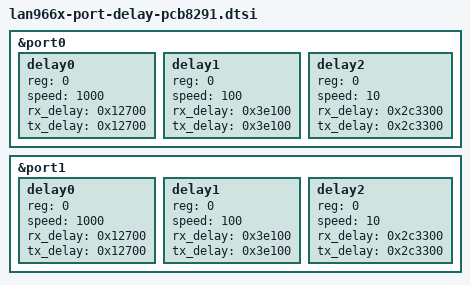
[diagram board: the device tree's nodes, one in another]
&port0 {
	#address-cells = <1>;
	#size-cells = <0>;

	delay0 {
		reg = <0>;
		speed = <1000>;
		rx_delay = <0x12700>;
		tx_delay = <0x12700>;
	};

	delay1 {
		reg = <0>;
		speed = <100>;
		rx_delay = <0x3e100>;
		tx_delay = <0x3e100>;
	};

	delay2 {
		reg = <0>;
		speed = <10>;
		rx_delay = <0x2c3300>;
		tx_delay = <0x2c3300>;
	};
};

&port1 {
	#address-cells = <1>;
	#size-cells = <0>;

	delay0 {
		reg = <0>;
		speed = <1000>;
		rx_delay = <0x12700>;
		tx_delay = <0x12700>;
	};

	delay1 {
		reg = <0>;
		speed = <100>;
		rx_delay = <0x3e100>;
		tx_delay = <0x3e100>;
	};

	delay2 {
		reg = <0>;
		speed = <10>;
		rx_delay = <0x2c3300>;
		tx_delay = <0x2c3300>;
	};
};
